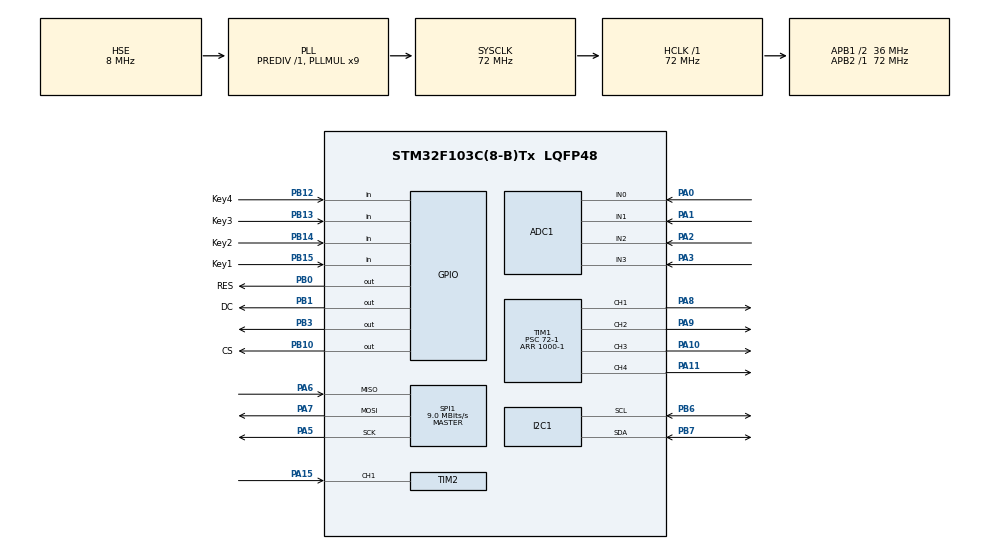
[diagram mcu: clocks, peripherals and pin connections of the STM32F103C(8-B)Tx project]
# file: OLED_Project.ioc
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ADC1.Channel-0\#ChannelRegularConversion=ADC_CHANNEL_0
ADC1.NbrOfConversionFlag=1
ADC1.Rank-0\#ChannelRegularConversion=1
ADC1.SamplingTime-0\#ChannelRegularConversion=ADC_SAMPLETIME_1CYCLE_5
ADC1.master=1
Mcu.Family=STM32F1
Mcu.Name=STM32F103C(8-B)Tx
Mcu.Package=LQFP48
NVIC.PriorityGroup=NVIC_PRIORITYGROUP_4
PA0-WKUP.Signal=ADCx_IN0
PA1.Signal=ADCx_IN1
PA10.Signal=S_TIM1_CH3
PA11.Signal=S_TIM1_CH4
PA13.Mode=Serial_Wire
PA13.Signal=SYS_JTMS-SWDIO
PA14.Mode=Serial_Wire
PA14.Signal=SYS_JTCK-SWCLK
PA15.Signal=S_TIM2_CH1_ETR
PA2.Signal=ADCx_IN2
PA3.Signal=ADCx_IN3
PA5.Mode=Full_Duplex_Master
PA5.Signal=SPI1_SCK
PA6.Mode=Full_Duplex_Master
PA6.Signal=SPI1_MISO
PA7.Mode=Full_Duplex_Master
PA7.Signal=SPI1_MOSI
PA8.Signal=S_TIM1_CH1
PA9.Signal=S_TIM1_CH2
PB0.GPIO_Label=RES
PB0.Signal=GPIO_Output
PB1.GPIO_Label=DC
PB1.Signal=GPIO_Output
PB10.GPIO_Label=CS
PB10.Signal=GPIO_Output
PB12.GPIO_Label=Key4
PB12.GPIO_PuPd=GPIO_PULLUP
PB12.Signal=GPIO_Input
PB13.GPIO_Label=Key3
PB13.GPIO_PuPd=GPIO_PULLUP
PB13.Signal=GPIO_Input
PB14.GPIO_Label=Key2
PB14.GPIO_PuPd=GPIO_PULLUP
PB14.Signal=GPIO_Input
PB15.GPIO_Label=Key1
PB15.GPIO_PuPd=GPIO_PULLUP
PB15.Signal=GPIO_Input
PB3.Signal=GPIO_Output
PB6.Mode=I2C
PB6.Signal=I2C1_SCL
PB7.Mode=I2C
PB7.Signal=I2C1_SDA
PD0-OSC_IN.Mode=HSE-External-Oscillator
PD0-OSC_IN.Signal=RCC_OSC_IN
PD1-OSC_OUT.Mode=HSE-External-Oscillator
PD1-OSC_OUT.Signal=RCC_OSC_OUT
ProjectManager.HeapSize=0x200
ProjectManager.StackSize=0x400
ProjectManager.TargetToolchain=Makefile
RCC.ADCPresc=RCC_ADCPCLK2_DIV6
RCC.AHBFreq_Value=72000000
RCC.APB1CLKDivider=RCC_HCLK_DIV2
RCC.APB1Freq_Value=36000000
RCC.APB1TimFreq_Value=72000000
RCC.APB2Freq_Value=72000000
RCC.APB2TimFreq_Value=72000000
RCC.HCLKFreq_Value=72000000
RCC.PLLMUL=RCC_PLL_MUL9
RCC.PLLSourceVirtual=RCC_PLLSOURCE_HSE
RCC.SYSCLKFreq_VALUE=72000000
RCC.SYSCLKSource=RCC_SYSCLKSOURCE_PLLCLK
RCC.USBFreq_Value=72000000
SH.ADCx_IN0.0=ADC1_IN0,IN0
SH.ADCx_IN1.0=ADC1_IN1,IN1
SH.ADCx_IN2.0=ADC1_IN2,IN2
SH.ADCx_IN3.0=ADC1_IN3,IN3
SH.S_TIM1_CH1.0=TIM1_CH1,PWM Generation1 CH1
SH.S_TIM1_CH2.0=TIM1_CH2,PWM Generation2 CH2
SH.S_TIM1_CH3.0=TIM1_CH3,PWM Generation3 CH3
SH.S_TIM1_CH4.0=TIM1_CH4,PWM Generation4 CH4
SH.S_TIM2_CH1_ETR.0=TIM2_CH1,Input_Capture1_from_TI1
SPI1.BaudRatePrescaler=SPI_BAUDRATEPRESCALER_8
SPI1.CalculateBaudRate=9.0 MBits/s
SPI1.Direction=SPI_DIRECTION_2LINES
SPI1.Mode=SPI_MODE_MASTER
SPI1.VirtualType=VM_MASTER
TIM1.AutoReloadPreload=TIM_AUTORELOAD_PRELOAD_ENABLE
TIM1.Channel-PWM\ Generation1\ CH1=TIM_CHANNEL_1
TIM1.Channel-PWM\ Generation2\ CH2=TIM_CHANNEL_2
TIM1.Channel-PWM\ Generation3\ CH3=TIM_CHANNEL_3
TIM1.Channel-PWM\ Generation4\ CH4=TIM_CHANNEL_4
TIM1.Period=1000-1
TIM1.Prescaler=72-1
TIM2.Channel-Input_Capture1_from_TI1=TIM_CHANNEL_1
VP_TIM1_VS_ClockSourceINT.Mode=Internal
VP_TIM2_VS_ClockSourceINT.Mode=Internal
board=custom

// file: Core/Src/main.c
/* USER CODE BEGIN Header */
/**
  ******************************************************************************
  * @file           : main.c
  * @brief          : Main program body
  ******************************************************************************
  * @attention
  *
  * Copyright (c) 2023 STMicroelectronics.
  * All rights reserved.
  *
  * This software is licensed under terms that can be found in the LICENSE file
  * in the root directory of this software component.
  * If no LICENSE file comes with this software, it is provided AS-IS.
  *
  ******************************************************************************
  */
/* USER CODE END Header */
#include "main.h"
#include "adc.h"
#include "i2c.h"
#include "spi.h"
#include "tim.h"
#include "gpio.h"

/* USER CODE BEGIN Includes */
#include "LED_Project.h"
/* USER CODE END Includes */

void SystemClock_Config(void);

int main(void)
{

  /* MCU Configuration--------------------------------------------------------*/

  /* Reset of all peripherals, Initializes the Flash interface and the Systick. */
  HAL_Init();

  /* Configure the system clock */
  SystemClock_Config();

  /* Initialize all configured peripherals */
  MX_GPIO_Init();
  MX_ADC1_Init();
  MX_I2C1_Init();
  MX_SPI1_Init();
  MX_TIM1_Init();
  MX_TIM2_Init();
  /* USER CODE BEGIN 2 */
  Task_Init();
  /* USER CODE END 2 */

  /* Infinite loop */
  while (1)
  {

    /* USER CODE BEGIN 3 */
    Task_Do();
  }
  /* USER CODE END 3 */
}

void SystemClock_Config(void)
{
  RCC_OscInitTypeDef RCC_OscInitStruct = {0};
  RCC_ClkInitTypeDef RCC_ClkInitStruct = {0};
  RCC_PeriphCLKInitTypeDef PeriphClkInit = {0};

  /** Initializes the RCC Oscillators according to the specified parameters
  * in the RCC_OscInitTypeDef structure.
  */
  RCC_OscInitStruct.OscillatorType = RCC_OSCILLATORTYPE_HSE;
  RCC_OscInitStruct.HSEState = RCC_HSE_ON;
  RCC_OscInitStruct.HSEPredivValue = RCC_HSE_PREDIV_DIV1;
  RCC_OscInitStruct.HSIState = RCC_HSI_ON;
  RCC_OscInitStruct.PLL.PLLState = RCC_PLL_ON;
  RCC_OscInitStruct.PLL.PLLSource = RCC_PLLSOURCE_HSE;
  RCC_OscInitStruct.PLL.PLLMUL = RCC_PLL_MUL9;
  if (HAL_RCC_OscConfig(&RCC_OscInitStruct) != HAL_OK)
  {
    Error_Handler();
  }

  /** Initializes the CPU, AHB and APB buses clocks
  */
  RCC_ClkInitStruct.ClockType = RCC_CLOCKTYPE_HCLK|RCC_CLOCKTYPE_SYSCLK
                              |RCC_CLOCKTYPE_PCLK1|RCC_CLOCKTYPE_PCLK2;
  RCC_ClkInitStruct.SYSCLKSource = RCC_SYSCLKSOURCE_PLLCLK;
  RCC_ClkInitStruct.AHBCLKDivider = RCC_SYSCLK_DIV1;
  RCC_ClkInitStruct.APB1CLKDivider = RCC_HCLK_DIV2;
  RCC_ClkInitStruct.APB2CLKDivider = RCC_HCLK_DIV1;

  if (HAL_RCC_ClockConfig(&RCC_ClkInitStruct, FLASH_LATENCY_2) != HAL_OK)
  {
    Error_Handler();
  }
  PeriphClkInit.PeriphClockSelection = RCC_PERIPHCLK_ADC;
  PeriphClkInit.AdcClockSelection = RCC_ADCPCLK2_DIV6;
  if (HAL_RCCEx_PeriphCLKConfig(&PeriphClkInit) != HAL_OK)
  {
    Error_Handler();
  }
}

void Error_Handler(void)
{
  __disable_irq();
  while (1)
  {
  }
}
